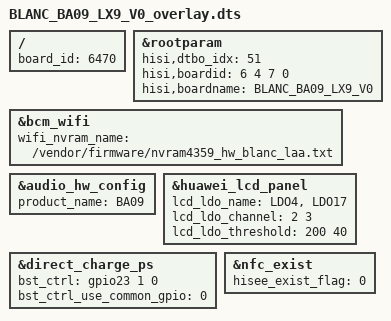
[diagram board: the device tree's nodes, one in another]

/**
 * Copyright (C) 2014 Hisilicon Ltd.
 *
 *  This program is free software; you can redistribute it and/or modify
 *  it under the terms of the GNU General Public License version 2 as
 *  publishhed by the Free Software Foundation.
 */

/dts-v1/;
/plugin/;
/include/ "BLANC_LX9_V3_9688_overlay.dtsi"

/ {
	board_id = <6470>;
};

&rootparam {
        hisi,dtbo_idx = <51>;
    hisi,boardid = <6 4 7 0>;
    hisi,boardname = "BLANC_BA09_LX9_V0";
};


&bcm_wifi {
	wifi_nvram_name = "/vendor/firmware/nvram4359_hw_blanc_laa.txt";
};

&audio_hw_config {
                product_name = "BA09";
};

&huawei_lcd_panel {
                lcd_ldo_name = "LDO4", "LDO17";
                lcd_ldo_channel = <2 3>;
                lcd_ldo_threshold = <200 40>;

};

&direct_charge_ps {
	bst_ctrl = <&gpio23 1 0>;
	bst_ctrl_use_common_gpio = <0>;
};

&nfc_exist {
	hisee_exist_flag = "0";
	status = "ok";
};
